# M2354 register map
File version: 1.0
Registers are 32-bit, read-write, reset 0x0 unless marked. A register's access mark holds for its fields unless they carry their own. Offsets are from the block's base; [hi:lo] are bit positions; {n}, {i} and the like mark numbered series.

## FMC — FMC Register Map
Base 0x4000C000
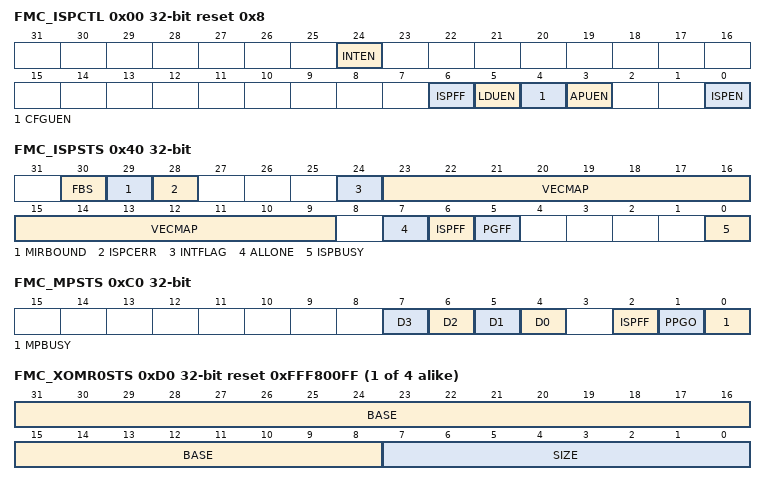
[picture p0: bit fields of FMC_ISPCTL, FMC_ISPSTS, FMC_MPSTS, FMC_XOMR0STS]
0x00 FMC_ISPCTL reset 0x8 — ISP Control Register
  [24] INTEN — Secure ISP INT Enable Bit (Write Protect). Note: This bit is write protected. Refer to the SYS_REGLCTL register.Before using INT,user needs to clear the INTFLAG(FMC_ISPSTS[24]) make sure INT happen at correct time.
    0=ISP INT Disabled; 1=ISP INT Enabled
  [6] ISPFF — ISP Fail Flag (Write Protect). This bit is set by hardware when a triggered ISP meets any of the following conditions: This bit needs to be cleared by writing 1 to it. APROM writes to itself if APUEN is set to 0. LDROM writes to itself if LDUEN is set to 0. CONFIG is erased/programmed if CFGUEN is set to 0. Page Erase command at LOCK mode with ICE connection. Erase or Program command at brown-out detected. Destination address is illegal, such as over an available range. Invalid ISP commands. APROM is erased/programmed if KEYLOCK is set to 1. LDROM is erased/programmed if KEYLOCK is set to 1. CONFIG is erased/programmed if KEYLOCK is set to 1 and KEYENROM[0] is 0. Read any content of boot loader with ICE connection. The address of block erase and bank erase is not in APROM. ISP CMD in XOM region, except mass erase, page erase and chksum command. The wrong setting of page erase ISP CMD in XOM. Violate XOM setting one time protection. Page erase ISP CMD in Secure/Non-secure region setting page. Mass erase when MERASE (CFG0[13]) is disabled. Page erase, mass erase, multi-word program or 64-bit word program in OTP. ISP conflict error. Note: This bit is write protected. Refer to the SYS_REGLCTL register.
  [5] LDUEN — LDROM Update Enable Bit (Write Protect). Note: This bit is write protected. Refer to the SYS_REGLCTL register.
    0=LDROM cannot be updated; 1=LDROM can be updated
  [4] CFGUEN — CONFIG Update Enable Bit (Write Protect). Note: This bit is write protected. Refer to the SYS_REGLCTL register.
    0=CONFIG cannot be updated; 1=CONFIG can be updated
  [3] APUEN — APROM Update Enable Bit (Write Protect). Note: This bit is write protected. Refer to the SYS_REGLCTL register.
    0=APROM cannot be updated when the chip runs in APROM; 1=APROM can be updated when the chip runs in APROM
  [0] ISPEN ro — ISP Enable Bit (Read Only). Note: This bit is read only to show ISP function enable.
    1=ISP function Enabled
0x04 FMC_ISPADDR — ISP Address Register
  [31:0] ISPADDR — ISP Address. The M2354 series is equipped with embedded Flash. ISPADDR[1:0] must be kept 00 for ISP 32-bit operation. ISPADDR[2:0] must be kept 000 for ISP 64-bit operation. For CRC32 Checksum Calculation command, this field is the Flash starting address for checksum calculation, 2 Kbytes alignment is necessary for CRC32 checksum calculation. For Flash32-bit Program, ISP address needs word alignment (4-byte). For Flash 64-bit Program, ISP address needs double word alignment (8-byte).
0x08 FMC_ISPDAT — ISP Data Register
  [31:0] ISPDAT — ISP Data. Write data to this register before ISP program operation. Read data from this register after ISP read operation.
0x0C FMC_ISPCMD — ISP Command Register
  [6:0] CMD — ISP Command. The ISP command table is shown below: The other commands are invalid.
    0=FLASH Read; 4=Read Unique ID; 8=Read Flash All-One Result; 11=Read Company ID; 12=Read Device ID; 13=Read Checksum; 33=FLASH 32-bit Program; 34=FLASH Page Erase. Erase any page in two banks, except for OTP; 35=FLASH Bank Erase. Erase all pages of APROM in BANK0 or BANK1; 40=Run Flash All-One Verification; 44=Bank REMAP; 45=Run Checksum Calculation; 46=Vector Remap; 64=FLASH 64-bit Read; 97=FLASH 64-bit Program
0x10 FMC_ISPTRG — ISP Trigger Control Register
  [0] ISPGO — ISP Start Trigger (Write Protect). Note: This bit is write protected. Refer to the SYS_REGLCTL register.
    0=ISP operation is finished; 1=ISP is progressed
0x18 FMC_FTCTL — Flash Access Time Control Register
  [9] CACHEINV — Flash Cache Invalidation (Write Protect). Note 1: Write 1 to start cache invalidation. The value will be changed to 0 once the process finishes. Note 2: This bit is write-protected. Refer to the SYS_REGLCTL register.
    0=Flash Cache Invalidation finished (default); 1=Flash Cache Invalidation
0x40 FMC_ISPSTS — ISP Status Register
  [30] FBS — Flash Bank Selection. This bit indicate which bank is selected to boot.
    0=Booting from BANK0; 1=Booting from BANK1
  [29] MIRBOUND — Mirror Boundary
    0=Mirror Boundary Disabled; 1=Mirror Boundary Enabled
  [28] ISPCERR — ISP Conflict Error. This bit shows when FMC is doing ISP operation.User can not access FMC_ISP_ADDR,FMC_ISPDAT,FMC_ISPCMD,FMC_ISPTRG. It would cause ISPFF.
  [24] INTFLAG — ISP Interuppt Flag. Note: This function needs to be enabled by FMC_ISPCTRL[24].
    0=ISP Not Finished; 1=ISP done or ISPFF set
  [23:9] VECMAP ro — Vector Page Mapping Address (Read Only). All access to 0x0000_0000~0x0000_01FF is remapped to the Flash memory address {VECMAP[14:0], 9'h000} ~ {VECMAP[14:0], 9'h1FF}
  [7] ALLONE — Flash All-one Verification Flag. This bit is set by hardware if all of Flash bits are 1, and clear if Flash bits are not all 1 after 'Run Flash All-One Verification' complete; this bit also can be clear by writing 1
    0=Flash bits are not all 1 after 'Run Flash All-One Verification' complete; 1=All of Flash bits are 1 after 'Run Flash All-One Verification' complete
  [6] ISPFF — ISP Fail Flag (Write Protect). This bit is the mirror of ISPFF (FMC_ISPCTL[6]), it needs to be cleared by writing 1 to FMC_ISPCTL[6] or FMC_ISPSTS[6]. This bit is set by hardware when a triggered ISP meets any of the following conditions: APROM writes to itself if APUEN is set to 0. LDROM writes to itself if LDUEN is set to 0. CONFIG is erased/programmed if CFGUEN is set to 0. Page Erase command at LOCK mode with ICE connection. Erase or Program command at brown-out detected. Destination address is illegal, such as over an available range. Invalid ISP commands. APROM is erased/programmed if KEYLOCK is set to 1. LDROM is erased/programmed if KEYLOCK is set to 1. CONFIG is erased/programmed if KEYLOCK is set to 1 and KEYENROM[0] is 0. Read any content of boot loader with ICE connection. The address of block erase and bank erase is not in APROM. ISP CMD in XOM region, except mass erase, page erase and chksum command. The wrong setting of page erase ISP CMD in XOM. Violate XOM setting one time protection. Page erase ISP CMD in Secure/Non-secure region setting page. Mass erase when MERASE (CFG0[13]) is disabled. Page erase, mass erase, multi-word program or 64-bit word program in OTP. ISP conflict error. Note: This bit is write protected. Refer to the SYS_REGLCTL register.
  [5] PGFF ro — Flash Program with Fast Verification Flag (Read Only). This bit is set if data is mismatched at ISP programming verification. This bit is clear by performing ISP Flash erase or ISP read CID operation
    0=Flash Program is success; 1=Flash Program is failed. Program data is different with data in the Flash memory
  [0] ISPBUSY ro — ISP Busy Flag (Read Only). Write 1 to start ISP operation and this bit will be cleared to 0 by hardware automatically when ISP operation is finished. This bit is the mirror of ISPGO(FMC_ISPTRG[0]).
    0=ISP operation is finished; 1=ISP is progressed
0x4C FMC_CYCCTL reset 0x1 — Flash Access Cycle Control Register
  [3:0] CYCLE — Flash Access Cycle Control (Write Protect). This register is updated by software.User needs to check the speed of HCLK and set the cycle 0. The optimized HCLK working frequency range is75~96 MHz. Note: This bit is write protected. Refer to the SYS_REGLCTL register.
    1=CPU access with one wait cycle if cache miss; Flash access cycle is 1;; 2=CPU access with two wait cycles if cache miss; Flash access cycle is 2;; 3=CPU access with three wait cycles if cache miss; Flash access cycle is 3;; 4=CPU access with four wait cycles if cache miss; Flash access cycle is 4;
0x80 FMC_MPDAT0 — ISP Data0 Register
  [31:0] ISPDAT0 — ISP Data 0. This register is the first 32-bit data for 32-bit/64-bit/multi-word programming, and it is also the mirror of FMC_ISPDAT, both registers keep the same data.
0x84 FMC_MPDAT1 — ISP Data1 Register
  [31:0] ISPDAT1 — ISP Data 1. This register is the second 32-bit data for 64-bit/multi-word programming.
0x88 FMC_MPDAT2 — ISP Data2 Register
  [31:0] ISPDAT2 — ISP Data 2. This register is the third 32-bit data for multi-word programming.
0x8C FMC_MPDAT3 — ISP Data3 Register
  [31:0] ISPDAT3 — ISP Data 3. This register is the fourth 32-bit data for multi-word programming.
0xC0 FMC_MPSTS ro — ISP Multi-program Status Register
  [n+4] D{n} (n=0..3) — ISP DATA {n} Flag (Read Only). This bit is set when FMC_MPDAT{n} is written and auto-cleared to 0 when the FMC_MPDAT{n} data is programmed to Flash complete.
    0=FMC_MPDAT{n} register is empty, or program to Flash complete; 1=FMC_MPDAT{n} register has been written, and not program to Flash complete
  [2] ISPFF — ISP Fail Flag (Read Only). This bit is the mirror of ISPFF (FMC_ISPCTL[6]), it needs to be cleared by writing 1 to FMC_ISPCTL[6] or FMC_ISPSTS[6]. This bit is set by hardware when a triggered ISP meets any of the following conditions: APROM writes to itself if APUEN is set to 0. LDROM writes to itself if LDUEN is set to 0. CONFIG is erased/programmed if CFGUEN is set to 0. Page Erase command at LOCK mode with ICE connection. Erase or Program command at brown-out detected. Destination address is illegal, such as over an available range. Invalid ISP commands. APROM is erased/programmed if KEYLOCK is set to 1. LDROM is erased/programmed if KEYLOCK is set to 1. CONFIG is erased/programmed if KEYLOCK is set to 1 and KEYENROM[0] is 0. Read any content of boot loader with ICE connection. The address of block erase and bank erase is not in APROM. ISP CMD in XOM region, except mass erase, page erase and chksum command. The wrong setting of page erase ISP CMD in XOM. Violate XOM setting one time protection. Page erase ISP CMD in Secure/Non-secure region setting page. Mass erase when MERASE (CFG0[13]) is disabled. Page erase, mass erase, multi-word program or 64-bit word program in OTP
  [1] PPGO — ISP Multi-program Status (Read Only)
    0=ISP multi-word program operation is not active; 1=ISP multi-word program operation is in progress
  [0] MPBUSY — ISP Multi-word Program Busy Flag (Read Only). Write 1 to start ISP Multi-Word program operation and this bit will be cleared to 0 by hardware automatically when ISP Multi-Word program operation is finished. This bit is the mirror of ISPGO(FMC_ISPTRG[0]).
    0=ISP Multi-Word program operation is finished; 1=ISP Multi-Word program operation is progressed
0xC4 FMC_MPADDR ro — ISP Multi-program Address Register
  [31:0] MPADDR — ISP Multi-word Program Address. MPADDR is the address of ISP multi-word program operation when ISPGO flag is 1. MPADDR will keep the final ISP address when ISP multi-word program is complete.
{0xD0+4i} FMC_XOMR{i}STS ro reset 0xFFF800FF (i=0..3) — XOM Region {i} Status Register
  [31:8] BASE — XOM Region {i} Base Address (Page-aligned). BASE is the base address of XOM Region {i}.
  [7:0] SIZE — XOM Region {i} Size (Page-aligned). SIZE is the page number of XOM Region {i}.
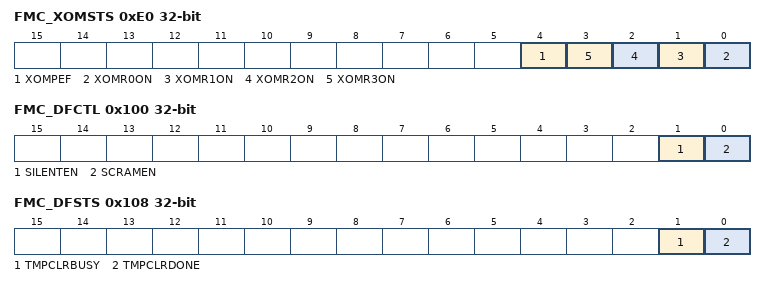
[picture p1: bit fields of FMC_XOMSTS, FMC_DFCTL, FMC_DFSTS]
0xE0 FMC_XOMSTS ro — XOM Status Register
  [4] XOMPEF — XOM Page Erase Function Fail. XOM page erase function status. If XOMPEF is set to 1, user needs to erase XOM region again.
    0=Sucess; 1=Fail
  [n] XOMR{n}ON (n=0..3) — XOM Region {n} On. XOM Region {n} active status.
    0=No active; 1=XOM region {n} is active
0x100 FMC_DFCTL — Data Flash Function Control
  [1] SILENTEN — Silent Access Enable Bit. User can set this bit to enable Silent access protection on Data Flash. Note that the Data Flash is formed as 4 pages of 1 Kbytes when silent access protection is enabled. Note: This bit is write protected. Refer to the SYS_REGLCTL register.
    0=Silent access Disabled; 1=Silent access Enabled
  [0] SCRAMEN — Data Scrambling Enable Bit. User can set this bit to enable Data scrambling protection on Data Flash. Note: This bit is write protected. Refer to the SYS_REGLCTL register.
    0=Data scrambling Disabled; 1=Data scrambling Enabled
0x108 FMC_DFSTS — Data Flash Status
  [1] TMPCLRBUSY ro — Data Flash Temper Attack Programming Busy Status (Read Only)
    0=Data Flash temper attack programming is not busy; 1=Data Flash temper attack programming is busy
  [0] TMPCLRDONE — Data Flash Temper Attack Programming Done
    0=Data Flash temper attack programming is not finished; 1=Data Flash temper attack programming is done, and user can write 1 to clear this bit
0x10C FMC_SCRKEY wo — Data Flash Scrambling Key
  [31:0] SCRKEY — Data Flash Scrambling Key (Write Only). 32-bit user defined data scrambling key for Data Flash. When data scrambling is enabled (FMC_DFCTL[0]), data in Data FLASH is scrambled when written and de-scrambled when read. Note: This bit is write protected. Refer to the SYS_REGLCTL register.
